# RX64M_TPU_Pilot register map
File version: 1.0
RX64M_TPU_Pilot peripheral registers generated from iodefine.h (pilot).
Registers are 8-bit, read-write, reset 0x0 unless marked. A register's access mark holds for its fields unless they carry their own. Offsets are from the block's base; lines under a group give offsets from that group; [hi:lo] are bit positions; {n}, {i} and the like mark numbered series; 'fields as' and 'values as' point back to an identical list; <NAME> marks a mode.

## Memory map
0x00088100 TPUA size 0x2
0x00088108 TPU0 size 0x18
0x00088108 TPU1 size 0x24
0x0008810A TPU2 size 0x32
0x0008810A TPU3 size 0x46
0x0008810C TPU4 size 0x50
0x0008810C TPU5 size 0x60

## TPU0
Base 0x00088108
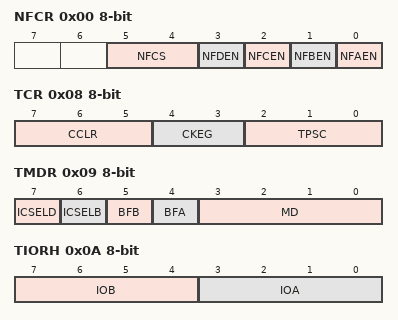
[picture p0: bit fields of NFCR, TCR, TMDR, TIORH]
0x00 NFCR
  [5:4] NFCS, [3] NFDEN, [2] NFCEN, [1] NFBEN, [0] NFAEN
0x08 TCR
  [7:5] CCLR, [4:3] CKEG, [2:0] TPSC
0x09 TMDR
  [7] ICSELD, [6] ICSELB, [5] BFB, [4] BFA, [3:0] MD
0x0A TIORH
  [7:4] IOB, [3:0] IOA
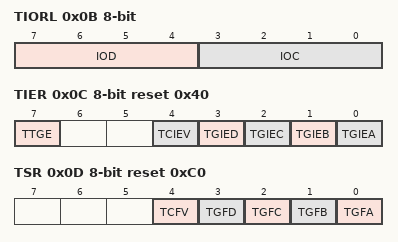
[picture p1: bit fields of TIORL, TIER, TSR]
0x0B TIORL
  [7:4] IOD, [3:0] IOC
0x0C TIER reset 0x40
  [7] TTGE, [4] TCIEV, [3] TGIED, [2] TGIEC, [1] TGIEB, [0] TGIEA
0x0D TSR reset 0xC0
  [4] TCFV, [3] TGFD, [2] TGFC, [1] TGFB, [0] TGFA
0x0E TCNT 16-bit
0x10 TGRA 16-bit reset 0xFFFF
0x12 TGRB 16-bit reset 0xFFFF
0x14 TGRC 16-bit reset 0xFFFF
0x16 TGRD 16-bit reset 0xFFFF

## TPU1
Base 0x00088108; alternate view of TPU0
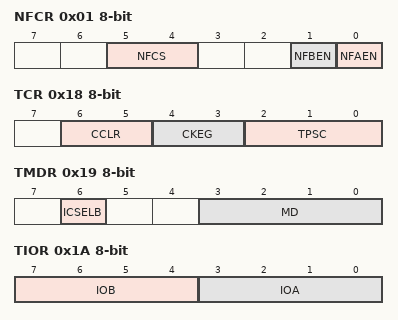
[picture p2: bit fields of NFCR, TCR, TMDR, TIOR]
0x01 NFCR
  [5:4] NFCS, [1] NFBEN, [0] NFAEN
0x18 TCR
  [6:5] CCLR, [4:3] CKEG, [2:0] TPSC
0x19 TMDR
  [6] ICSELB, [3:0] MD
0x1A TIOR
  [7:4] IOB, [3:0] IOA
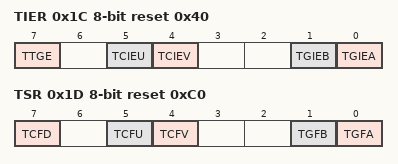
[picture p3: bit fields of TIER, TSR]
0x1C TIER reset 0x40
  [7] TTGE, [5] TCIEU, [4] TCIEV, [1] TGIEB, [0] TGIEA
0x1D TSR reset 0xC0
  [7] TCFD, [5] TCFU, [4] TCFV, [1] TGFB, [0] TGFA
0x1E TCNT 16-bit
0x20 TGRA 16-bit reset 0xFFFF
0x22 TGRB 16-bit reset 0xFFFF

## TPU2
Base 0x0008810A
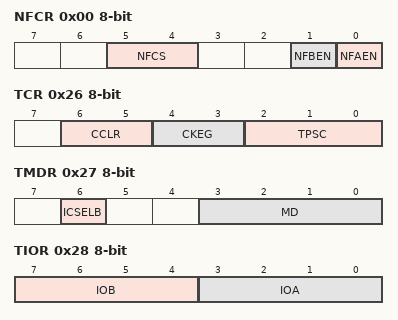
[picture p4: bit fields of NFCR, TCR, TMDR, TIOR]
0x00 NFCR
  [5:4] NFCS, [1] NFBEN, [0] NFAEN
0x26 TCR
  [6:5] CCLR, [4:3] CKEG, [2:0] TPSC
0x27 TMDR
  [6] ICSELB, [3:0] MD
0x28 TIOR
  [7:4] IOB, [3:0] IOA
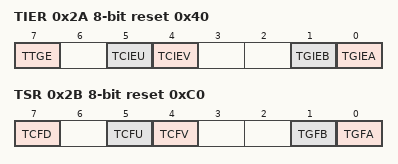
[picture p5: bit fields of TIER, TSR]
0x2A TIER reset 0x40
  [7] TTGE, [5] TCIEU, [4] TCIEV, [1] TGIEB, [0] TGIEA
0x2B TSR reset 0xC0
  [7] TCFD, [5] TCFU, [4] TCFV, [1] TGFB, [0] TGFA
0x2C TCNT 16-bit
0x2E TGRA 16-bit reset 0xFFFF
0x30 TGRB 16-bit reset 0xFFFF

## TPU3
Base 0x0008810A; alternate view of TPU2
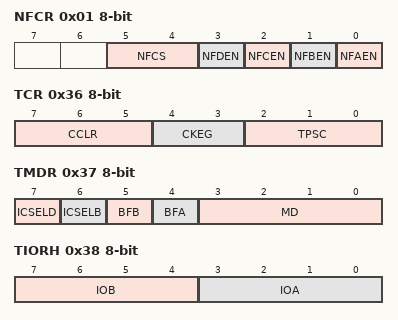
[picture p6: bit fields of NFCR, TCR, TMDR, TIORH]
0x01 NFCR
  [5:4] NFCS, [3] NFDEN, [2] NFCEN, [1] NFBEN, [0] NFAEN
0x36 TCR
  [7:5] CCLR, [4:3] CKEG, [2:0] TPSC
0x37 TMDR
  [7] ICSELD, [6] ICSELB, [5] BFB, [4] BFA, [3:0] MD
0x38 TIORH
  [7:4] IOB, [3:0] IOA
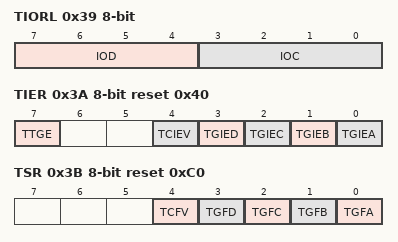
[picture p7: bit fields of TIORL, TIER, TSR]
0x39 TIORL
  [7:4] IOD, [3:0] IOC
0x3A TIER reset 0x40
  [7] TTGE, [4] TCIEV, [3] TGIED, [2] TGIEC, [1] TGIEB, [0] TGIEA
0x3B TSR reset 0xC0
  [4] TCFV, [3] TGFD, [2] TGFC, [1] TGFB, [0] TGFA
0x3C TCNT 16-bit
0x3E TGRA 16-bit reset 0xFFFF
0x40 TGRB 16-bit reset 0xFFFF
0x42 TGRC 16-bit reset 0xFFFF
0x44 TGRD 16-bit reset 0xFFFF

## TPU4
Base 0x0008810C
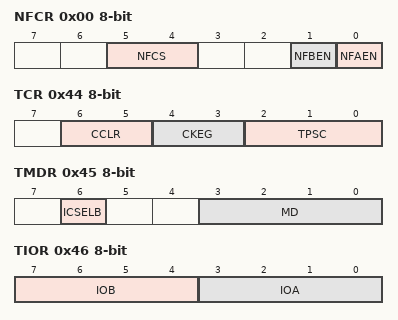
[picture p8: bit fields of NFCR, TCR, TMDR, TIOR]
0x00 NFCR
  [5:4] NFCS, [1] NFBEN, [0] NFAEN
0x44 TCR
  [6:5] CCLR, [4:3] CKEG, [2:0] TPSC
0x45 TMDR
  [6] ICSELB, [3:0] MD
0x46 TIOR
  [7:4] IOB, [3:0] IOA
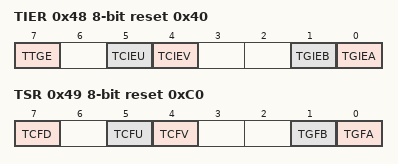
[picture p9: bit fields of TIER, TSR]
0x48 TIER reset 0x40
  [7] TTGE, [5] TCIEU, [4] TCIEV, [1] TGIEB, [0] TGIEA
0x49 TSR reset 0xC0
  [7] TCFD, [5] TCFU, [4] TCFV, [1] TGFB, [0] TGFA
0x4A TCNT 16-bit
0x4C TGRA 16-bit reset 0xFFFF
0x4E TGRB 16-bit reset 0xFFFF

## TPU5
Base 0x0008810C; alternate view of TPU4
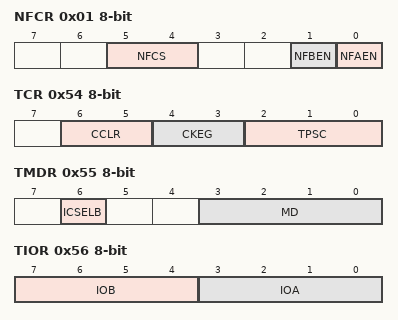
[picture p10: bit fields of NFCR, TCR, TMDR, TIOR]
0x01 NFCR
  [5:4] NFCS, [1] NFBEN, [0] NFAEN
0x54 TCR
  [6:5] CCLR, [4:3] CKEG, [2:0] TPSC
0x55 TMDR
  [6] ICSELB, [3:0] MD
0x56 TIOR
  [7:4] IOB, [3:0] IOA
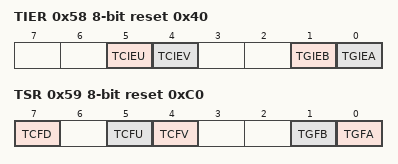
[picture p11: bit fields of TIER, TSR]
0x58 TIER reset 0x40
  [5] TCIEU, [4] TCIEV, [1] TGIEB, [0] TGIEA
0x59 TSR reset 0xC0
  [7] TCFD, [5] TCFU, [4] TCFV, [1] TGFB, [0] TGFA
0x5A TCNT 16-bit
0x5C TGRA 16-bit reset 0xFFFF
0x5E TGRB 16-bit reset 0xFFFF

## TPUA
Base 0x00088100
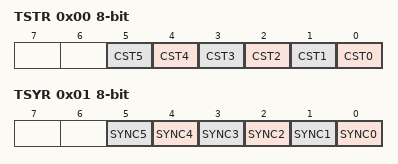
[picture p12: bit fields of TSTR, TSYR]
0x00 TSTR
  [n] CST{n} (n=0..5)
0x01 TSYR
  [n] SYNC{n} (n=0..5)
